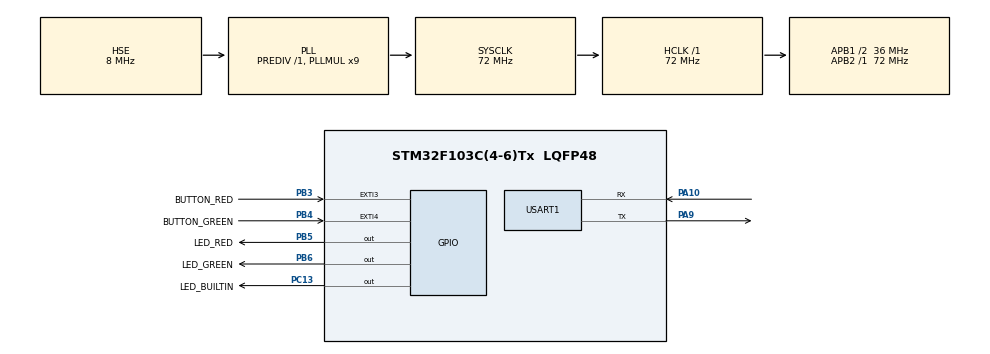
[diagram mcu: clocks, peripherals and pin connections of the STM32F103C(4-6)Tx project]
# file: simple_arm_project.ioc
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FREERTOS.Tasks01=defaultTask,8,128,StartDefaultTask,Default,NULL,Dynamic,NULL,NULL
Mcu.Family=STM32F1
Mcu.Name=STM32F103C(4-6)Tx
Mcu.Package=LQFP48
NVIC.EXTI3_IRQn=true\:5\:0\:false\:false\:true\:true\:true\:true\:true
NVIC.EXTI4_IRQn=true\:5\:0\:false\:false\:true\:true\:true\:true\:true
NVIC.PriorityGroup=NVIC_PRIORITYGROUP_4
NVIC.TIM3_IRQn=true\:15\:0\:false\:false\:true\:false\:false\:true\:true
NVIC.TimeBase=TIM3_IRQn
NVIC.TimeBaseIP=TIM3
NVIC.USART1_IRQn=true\:5\:0\:false\:false\:true\:true\:true\:true\:true
PA10.Mode=Asynchronous
PA10.Signal=USART1_RX
PA13.Mode=Serial_Wire
PA13.Signal=SYS_JTMS-SWDIO
PA14.Mode=Serial_Wire
PA14.Signal=SYS_JTCK-SWCLK
PA9.Mode=Asynchronous
PA9.Signal=USART1_TX
PB3.GPIO_Label=BUTTON_RED
PB3.GPIO_ModeDefaultEXTI=GPIO_MODE_IT_FALLING
PB3.GPIO_PuPd=GPIO_PULLUP
PB3.Signal=GPXTI3
PB4.GPIO_Label=BUTTON_GREEN
PB4.GPIO_ModeDefaultEXTI=GPIO_MODE_IT_FALLING
PB4.GPIO_PuPd=GPIO_PULLUP
PB4.Signal=GPXTI4
PB5.GPIO_Label=LED_RED
PB5.GPIO_ModeDefaultOutputPP=GPIO_MODE_OUTPUT_OD
PB5.GPIO_PuPd=GPIO_NOPULL
PB5.PinState=GPIO_PIN_SET
PB5.Signal=GPIO_Output
PB6.GPIO_Label=LED_GREEN
PB6.GPIO_ModeDefaultOutputPP=GPIO_MODE_OUTPUT_OD
PB6.GPIO_PuPd=GPIO_NOPULL
PB6.PinState=GPIO_PIN_SET
PB6.Signal=GPIO_Output
PC13-TAMPER-RTC.GPIO_Label=LED_BUILTIN
PC13-TAMPER-RTC.PinState=GPIO_PIN_SET
PC13-TAMPER-RTC.Signal=GPIO_Output
PD0-OSC_IN.Mode=HSE-External-Oscillator
PD0-OSC_IN.Signal=RCC_OSC_IN
PD1-OSC_OUT.Mode=HSE-External-Oscillator
PD1-OSC_OUT.Signal=RCC_OSC_OUT
ProjectManager.HeapSize=0x200
ProjectManager.StackSize=0x400
ProjectManager.TargetToolchain=CMake
RCC.AHBFreq_Value=72000000
RCC.APB1CLKDivider=RCC_HCLK_DIV2
RCC.APB1Freq_Value=36000000
RCC.APB1TimFreq_Value=72000000
RCC.APB2Freq_Value=72000000
RCC.APB2TimFreq_Value=72000000
RCC.HCLKFreq_Value=72000000
RCC.PLLMUL=RCC_PLL_MUL9
RCC.PLLSourceVirtual=RCC_PLLSOURCE_HSE
RCC.SYSCLKFreq_VALUE=72000000
RCC.SYSCLKSource=RCC_SYSCLKSOURCE_PLLCLK
RCC.USBFreq_Value=72000000
USART1.VirtualMode=VM_ASYNC
VP_FREERTOS_VS_CMSIS_V2.Mode=CMSIS_V2
VP_SYS_VS_tim3.Mode=TIM3
board=custom

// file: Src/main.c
/* USER CODE BEGIN Header */
/**
  ******************************************************************************
  * @file           : main.c
  * @brief          : Main program body
  ******************************************************************************
  * @attention
  *
  * Copyright (c) 2026 STMicroelectronics.
  * All rights reserved.
  *
  * This software is licensed under terms that can be found in the LICENSE file
  * in the root directory of this software component.
  * If no LICENSE file comes with this software, it is provided AS-IS.
  *
  ******************************************************************************
  */
/* USER CODE END Header */
#include "main.h"
#include "cmsis_os.h"

/* USER CODE BEGIN Includes */
#include "des_controller.h"
/* USER CODE END Includes */

/* USER CODE BEGIN PD */
// Disable default task creation forced by STM32CubeMX.
#undef osThreadNew
#define osThreadNew(a, b, c) (NULL)
/* USER CODE END PD */

UART_HandleTypeDef huart1;

/* Definitions for defaultTask */
osThreadId_t defaultTaskHandle;
const osThreadAttr_t defaultTask_attributes = {
  .name = "defaultTask",
  .stack_size = 128 * 4,
  .priority = (osPriority_t) osPriorityLow,
};

void SystemClock_Config(void);
static void MX_GPIO_Init(void);
static void MX_USART1_UART_Init(void);
void StartDefaultTask(void *argument);

int main(void)
{

  /* MCU Configuration--------------------------------------------------------*/

  /* Reset of all peripherals, Initializes the Flash interface and the Systick. */
  HAL_Init();

  /* Configure the system clock */
  SystemClock_Config();

  /* Initialize all configured peripherals */
  MX_GPIO_Init();
  MX_USART1_UART_Init();

  /* Init scheduler */
  osKernelInitialize();

  /* Create the thread(s) */
  /* creation of defaultTask */
  defaultTaskHandle = osThreadNew(StartDefaultTask, NULL, &defaultTask_attributes);

  /* USER CODE BEGIN RTOS_THREADS */
  DesControllerSetup();
  /* USER CODE END RTOS_THREADS */

  /* Start scheduler */
  osKernelStart();

  /* We should never get here as control is now taken by the scheduler */

  /* Infinite loop */
  while (1)
  {

  }
}

void SystemClock_Config(void)
{
  RCC_OscInitTypeDef RCC_OscInitStruct = {0};
  RCC_ClkInitTypeDef RCC_ClkInitStruct = {0};

  /** Initializes the RCC Oscillators according to the specified parameters
  * in the RCC_OscInitTypeDef structure.
  */
  RCC_OscInitStruct.OscillatorType = RCC_OSCILLATORTYPE_HSE;
  RCC_OscInitStruct.HSEState = RCC_HSE_ON;
  RCC_OscInitStruct.HSEPredivValue = RCC_HSE_PREDIV_DIV1;
  RCC_OscInitStruct.HSIState = RCC_HSI_ON;
  RCC_OscInitStruct.PLL.PLLState = RCC_PLL_ON;
  RCC_OscInitStruct.PLL.PLLSource = RCC_PLLSOURCE_HSE;
  RCC_OscInitStruct.PLL.PLLMUL = RCC_PLL_MUL9;
  if (HAL_RCC_OscConfig(&RCC_OscInitStruct) != HAL_OK)
  {
    Error_Handler();
  }

  /** Initializes the CPU, AHB and APB buses clocks
  */
  RCC_ClkInitStruct.ClockType = RCC_CLOCKTYPE_HCLK|RCC_CLOCKTYPE_SYSCLK
                              |RCC_CLOCKTYPE_PCLK1|RCC_CLOCKTYPE_PCLK2;
  RCC_ClkInitStruct.SYSCLKSource = RCC_SYSCLKSOURCE_PLLCLK;
  RCC_ClkInitStruct.AHBCLKDivider = RCC_SYSCLK_DIV1;
  RCC_ClkInitStruct.APB1CLKDivider = RCC_HCLK_DIV2;
  RCC_ClkInitStruct.APB2CLKDivider = RCC_HCLK_DIV1;

  if (HAL_RCC_ClockConfig(&RCC_ClkInitStruct, FLASH_LATENCY_2) != HAL_OK)
  {
    Error_Handler();
  }
}

static void MX_USART1_UART_Init(void)
{

  huart1.Instance = USART1;
  huart1.Init.BaudRate = 115200;
  huart1.Init.WordLength = UART_WORDLENGTH_8B;
  huart1.Init.StopBits = UART_STOPBITS_1;
  huart1.Init.Parity = UART_PARITY_NONE;
  huart1.Init.Mode = UART_MODE_TX_RX;
  huart1.Init.HwFlowCtl = UART_HWCONTROL_NONE;
  huart1.Init.OverSampling = UART_OVERSAMPLING_16;
  if (HAL_UART_Init(&huart1) != HAL_OK)
  {
    Error_Handler();
  }

}

static void MX_GPIO_Init(void)
{
  GPIO_InitTypeDef GPIO_InitStruct = {0};

  /* GPIO Ports Clock Enable */
  __HAL_RCC_GPIOC_CLK_ENABLE();
  __HAL_RCC_GPIOD_CLK_ENABLE();
  __HAL_RCC_GPIOA_CLK_ENABLE();
  __HAL_RCC_GPIOB_CLK_ENABLE();

  /*Configure GPIO pin Output Level */
  HAL_GPIO_WritePin(LED_BUILTIN_GPIO_Port, LED_BUILTIN_Pin, GPIO_PIN_SET);

  /*Configure GPIO pin Output Level */
  HAL_GPIO_WritePin(GPIOB, LED_RED_Pin|LED_GREEN_Pin, GPIO_PIN_SET);

  /*Configure GPIO pin : LED_BUILTIN_Pin */
  GPIO_InitStruct.Pin = LED_BUILTIN_Pin;
  GPIO_InitStruct.Mode = GPIO_MODE_OUTPUT_PP;
  GPIO_InitStruct.Pull = GPIO_NOPULL;
  GPIO_InitStruct.Speed = GPIO_SPEED_FREQ_LOW;
  HAL_GPIO_Init(LED_BUILTIN_GPIO_Port, &GPIO_InitStruct);

  /*Configure GPIO pins : BUTTON_RED_Pin BUTTON_GREEN_Pin */
  GPIO_InitStruct.Pin = BUTTON_RED_Pin|BUTTON_GREEN_Pin;
  GPIO_InitStruct.Mode = GPIO_MODE_IT_FALLING;
  GPIO_InitStruct.Pull = GPIO_PULLUP;
  HAL_GPIO_Init(GPIOB, &GPIO_InitStruct);

  /*Configure GPIO pins : LED_RED_Pin LED_GREEN_Pin */
  GPIO_InitStruct.Pin = LED_RED_Pin|LED_GREEN_Pin;
  GPIO_InitStruct.Mode = GPIO_MODE_OUTPUT_OD;
  GPIO_InitStruct.Pull = GPIO_NOPULL;
  GPIO_InitStruct.Speed = GPIO_SPEED_FREQ_LOW;
  HAL_GPIO_Init(GPIOB, &GPIO_InitStruct);

  /* EXTI interrupt init*/
  HAL_NVIC_SetPriority(EXTI3_IRQn, 5, 0);
  HAL_NVIC_EnableIRQ(EXTI3_IRQn);

  HAL_NVIC_SetPriority(EXTI4_IRQn, 5, 0);
  HAL_NVIC_EnableIRQ(EXTI4_IRQn);

}

void StartDefaultTask(void *argument)
{
  for(;;)
  {
    osDelay(1);
  }
}

void HAL_TIM_PeriodElapsedCallback(TIM_HandleTypeDef *htim)
{
  if (htim->Instance == TIM3)
  {
    HAL_IncTick();
  }
}

void Error_Handler(void)
{
  __disable_irq();
  while (1)
  {
  }
}
